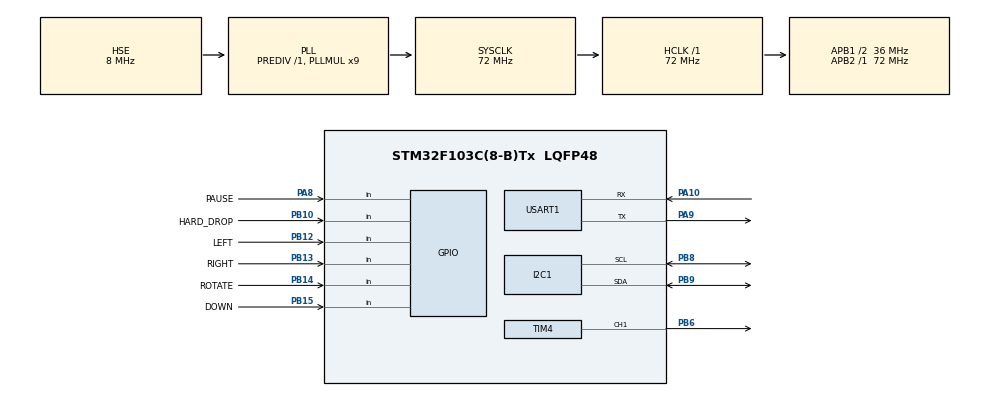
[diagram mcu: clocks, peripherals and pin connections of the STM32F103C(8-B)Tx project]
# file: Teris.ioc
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FREERTOS.Queues01=xInputQueue,16,uint16_t,0,Dynamic,NULL,NULL;xFrameQueue,1,uint16_t,0,Dynamic,NULL,NULL
FREERTOS.Tasks01=InputTask,27,192,StartInputTask,Default,NULL,Dynamic,NULL,NULL;GameTask,26,320,StartGameTask,Default,NULL,Dynamic,NULL,NULL;DisplayTask,25,384,StartDisplayTask,Default,NULL,Dynamic,NULL,NULL
FREERTOS.configCHECK_FOR_STACK_OVERFLOW=2
FREERTOS.configIDLE_SHOULD_YIELD=0
FREERTOS.configTOTAL_HEAP_SIZE=8192
FREERTOS.configUSE_MALLOC_FAILED_HOOK=1
Mcu.Family=STM32F1
Mcu.Name=STM32F103C(8-B)Tx
Mcu.Package=LQFP48
NVIC.PriorityGroup=NVIC_PRIORITYGROUP_4
NVIC.TIM2_IRQn=true\:15\:0\:false\:false\:true\:false\:false\:true\:true
NVIC.TimeBase=TIM2_IRQn
NVIC.TimeBaseIP=TIM2
NVIC.USART1_IRQn=true\:6\:0\:false\:false\:true\:true\:true\:true
PA10.Mode=Asynchronous
PA10.Signal=USART1_RX
PA13.Mode=Serial_Wire
PA13.Signal=SYS_JTMS-SWDIO
PA14.Mode=Serial_Wire
PA14.Signal=SYS_JTCK-SWCLK
PA8.GPIO_Label=PAUSE
PA8.GPIO_PuPd=GPIO_PULLUP
PA8.Signal=GPIO_Input
PA9.Mode=Asynchronous
PA9.Signal=USART1_TX
PB10.GPIO_Label=HARD_DROP
PB10.GPIO_PuPd=GPIO_PULLUP
PB10.Signal=GPIO_Input
PB12.GPIO_Label=LEFT
PB12.GPIO_PuPd=GPIO_PULLUP
PB12.Signal=GPIO_Input
PB13.GPIO_Label=RIGHT
PB13.GPIO_PuPd=GPIO_PULLUP
PB13.Signal=GPIO_Input
PB14.GPIO_Label=ROTATE
PB14.GPIO_PuPd=GPIO_PULLUP
PB14.Signal=GPIO_Input
PB15.GPIO_Label=DOWN
PB15.GPIO_PuPd=GPIO_PULLUP
PB15.Signal=GPIO_Input
PB6.Signal=S_TIM4_CH1
PB8.Mode=I2C
PB8.Signal=I2C1_SCL
PB9.Mode=I2C
PB9.Signal=I2C1_SDA
PD0-OSC_IN.Mode=HSE-External-Oscillator
PD0-OSC_IN.Signal=RCC_OSC_IN
PD1-OSC_OUT.Mode=HSE-External-Oscillator
PD1-OSC_OUT.Signal=RCC_OSC_OUT
ProjectManager.HeapSize=0x200
ProjectManager.StackSize=0x400
ProjectManager.TargetToolchain=MDK-ARM V5.32
RCC.AHBFreq_Value=72000000
RCC.APB1CLKDivider=RCC_HCLK_DIV2
RCC.APB1Freq_Value=36000000
RCC.APB1TimFreq_Value=72000000
RCC.APB2Freq_Value=72000000
RCC.APB2TimFreq_Value=72000000
RCC.HCLKFreq_Value=72000000
RCC.PLLMUL=RCC_PLL_MUL9
RCC.PLLSourceVirtual=RCC_PLLSOURCE_HSE
RCC.SYSCLKFreq_VALUE=72000000
RCC.SYSCLKSource=RCC_SYSCLKSOURCE_PLLCLK
RCC.USBFreq_Value=72000000
SH.S_TIM4_CH1.0=TIM4_CH1,PWM Generation1 CH1
TIM4.Channel-PWM\ Generation1\ CH1=TIM_CHANNEL_1
TIM4.OCPolarity-PWM\ Generation1\ CH1=TIM_OCPOLARITY_LOW
TIM4.Period=999
TIM4.Prescaler=71
USART1.VirtualMode=VM_ASYNC
VP_FREERTOS_VS_CMSIS_V2.Mode=CMSIS_V2
VP_SYS_VS_tim2.Mode=TIM2
board=custom

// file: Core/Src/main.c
/* USER CODE BEGIN Header */
/**
  ******************************************************************************
  * @file           : main.c
  * @brief          : Main program body
  ******************************************************************************
  * @attention
  *
  * Copyright (c) 2026 STMicroelectronics.
  * All rights reserved.
  *
  * This software is licensed under terms that can be found in the LICENSE file
  * in the root directory of this software component.
  * If no LICENSE file comes with this software, it is provided AS-IS.
  *
  ******************************************************************************
  */
/* USER CODE END Header */
#include "main.h"
#include "cmsis_os.h"

/* USER CODE BEGIN Includes */
#include "app_shared.h"
#include "app_diagnostics.h"

/* USER CODE END Includes */

I2C_HandleTypeDef hi2c1;

TIM_HandleTypeDef htim4;

UART_HandleTypeDef huart1;

/* Definitions for InputTask */
osThreadId_t InputTaskHandle;
const osThreadAttr_t InputTask_attributes = {
  .name = "InputTask",
  .stack_size = 192 * 4,
  .priority = (osPriority_t) osPriorityNormal3,
};
/* Definitions for GameTask */
osThreadId_t GameTaskHandle;
const osThreadAttr_t GameTask_attributes = {
  .name = "GameTask",
  .stack_size = 320 * 4,
  .priority = (osPriority_t) osPriorityNormal2,
};
/* Definitions for DisplayTask */
osThreadId_t DisplayTaskHandle;
const osThreadAttr_t DisplayTask_attributes = {
  .name = "DisplayTask",
  .stack_size = 384 * 4,
  .priority = (osPriority_t) osPriorityNormal1,
};
/* Definitions for xInputQueue */
osMessageQueueId_t xInputQueueHandle;
const osMessageQueueAttr_t xInputQueue_attributes = {
  .name = "xInputQueue"
};
/* Definitions for xFrameQueue */
osMessageQueueId_t xFrameQueueHandle;
const osMessageQueueAttr_t xFrameQueue_attributes = {
  .name = "xFrameQueue"
};

void SystemClock_Config(void);
static void MX_GPIO_Init(void);
static void MX_I2C1_Init(void);
static void MX_TIM4_Init(void);
static void MX_USART1_UART_Init(void);
void StartInputTask(void *argument);
void StartGameTask(void *argument);
void StartDisplayTask(void *argument);

int main(void)
{

  /* MCU Configuration--------------------------------------------------------*/

  /* Reset of all peripherals, Initializes the Flash interface and the Systick. */
  HAL_Init();

  /* Configure the system clock */
  SystemClock_Config();

  /* Initialize all configured peripherals */
  MX_GPIO_Init();
  MX_I2C1_Init();
  MX_TIM4_Init();
  MX_USART1_UART_Init();

  /* Init scheduler */
  if (osKernelInitialize()!=osOK) Error_Handler();

  /* Create the queue(s) */
  /* creation of xInputQueue */
  xInputQueueHandle = osMessageQueueNew (16, sizeof(uint16_t), &xInputQueue_attributes);

  /* creation of xFrameQueue */
  xFrameQueueHandle = osMessageQueueNew (1, sizeof(uint16_t), &xFrameQueue_attributes);

  /* Create the thread(s) */
  /* creation of InputTask */
  InputTaskHandle = osThreadNew(StartInputTask, NULL, &InputTask_attributes);

  /* creation of GameTask */
  GameTaskHandle = osThreadNew(StartGameTask, NULL, &GameTask_attributes);

  /* creation of DisplayTask */
  DisplayTaskHandle = osThreadNew(StartDisplayTask, NULL, &DisplayTask_attributes);

  /* USER CODE BEGIN RTOS_THREADS */
  if (!xInputQueueHandle || !xFrameQueueHandle || !InputTaskHandle ||
      !GameTaskHandle || !DisplayTaskHandle) app_fault(APP_FAULT_RTOS);
  /* add threads, ... */
  /* USER CODE END RTOS_THREADS */

  /* Start scheduler */
  if (osKernelStart()!=osOK) app_fault(APP_FAULT_RTOS);

  /* We should never get here as control is now taken by the scheduler */

  /* Infinite loop */
  while (1)
  {

  }
}

void SystemClock_Config(void)
{
  RCC_OscInitTypeDef RCC_OscInitStruct = {0};
  RCC_ClkInitTypeDef RCC_ClkInitStruct = {0};

  /** Initializes the RCC Oscillators according to the specified parameters
  * in the RCC_OscInitTypeDef structure.
  */
  RCC_OscInitStruct.OscillatorType = RCC_OSCILLATORTYPE_HSE;
  RCC_OscInitStruct.HSEState = RCC_HSE_ON;
  RCC_OscInitStruct.HSEPredivValue = RCC_HSE_PREDIV_DIV1;
  RCC_OscInitStruct.HSIState = RCC_HSI_ON;
  RCC_OscInitStruct.PLL.PLLState = RCC_PLL_ON;
  RCC_OscInitStruct.PLL.PLLSource = RCC_PLLSOURCE_HSE;
  RCC_OscInitStruct.PLL.PLLMUL = RCC_PLL_MUL9;
  if (HAL_RCC_OscConfig(&RCC_OscInitStruct) != HAL_OK)
  {
    Error_Handler();
  }

  /** Initializes the CPU, AHB and APB buses clocks
  */
  RCC_ClkInitStruct.ClockType = RCC_CLOCKTYPE_HCLK|RCC_CLOCKTYPE_SYSCLK
                              |RCC_CLOCKTYPE_PCLK1|RCC_CLOCKTYPE_PCLK2;
  RCC_ClkInitStruct.SYSCLKSource = RCC_SYSCLKSOURCE_PLLCLK;
  RCC_ClkInitStruct.AHBCLKDivider = RCC_SYSCLK_DIV1;
  RCC_ClkInitStruct.APB1CLKDivider = RCC_HCLK_DIV2;
  RCC_ClkInitStruct.APB2CLKDivider = RCC_HCLK_DIV1;

  if (HAL_RCC_ClockConfig(&RCC_ClkInitStruct, FLASH_LATENCY_2) != HAL_OK)
  {
    Error_Handler();
  }
}

static void MX_I2C1_Init(void)
{

  hi2c1.Instance = I2C1;
  hi2c1.Init.ClockSpeed = 100000;
  hi2c1.Init.DutyCycle = I2C_DUTYCYCLE_2;
  hi2c1.Init.OwnAddress1 = 0;
  hi2c1.Init.AddressingMode = I2C_ADDRESSINGMODE_7BIT;
  hi2c1.Init.DualAddressMode = I2C_DUALADDRESS_DISABLE;
  hi2c1.Init.OwnAddress2 = 0;
  hi2c1.Init.GeneralCallMode = I2C_GENERALCALL_DISABLE;
  hi2c1.Init.NoStretchMode = I2C_NOSTRETCH_DISABLE;
  if (HAL_I2C_Init(&hi2c1) != HAL_OK)
  {
    Error_Handler();
  }

}

static void MX_TIM4_Init(void)
{

  TIM_MasterConfigTypeDef sMasterConfig = {0};
  TIM_OC_InitTypeDef sConfigOC = {0};

  htim4.Instance = TIM4;
  htim4.Init.Prescaler = 71;
  htim4.Init.CounterMode = TIM_COUNTERMODE_UP;
  htim4.Init.Period = 999;
  htim4.Init.ClockDivision = TIM_CLOCKDIVISION_DIV1;
  htim4.Init.AutoReloadPreload = TIM_AUTORELOAD_PRELOAD_DISABLE;
  if (HAL_TIM_PWM_Init(&htim4) != HAL_OK)
  {
    Error_Handler();
  }
  sMasterConfig.MasterOutputTrigger = TIM_TRGO_RESET;
  sMasterConfig.MasterSlaveMode = TIM_MASTERSLAVEMODE_DISABLE;
  if (HAL_TIMEx_MasterConfigSynchronization(&htim4, &sMasterConfig) != HAL_OK)
  {
    Error_Handler();
  }
  sConfigOC.OCMode = TIM_OCMODE_PWM1;
  sConfigOC.Pulse = 0;
  sConfigOC.OCPolarity = TIM_OCPOLARITY_HIGH;
  sConfigOC.OCFastMode = TIM_OCFAST_DISABLE;
  if (HAL_TIM_PWM_ConfigChannel(&htim4, &sConfigOC, TIM_CHANNEL_1) != HAL_OK)
  {
    Error_Handler();
  }
  HAL_TIM_MspPostInit(&htim4);

}

static void MX_USART1_UART_Init(void)
{

  huart1.Instance = USART1;
  huart1.Init.BaudRate = 115200;
  huart1.Init.WordLength = UART_WORDLENGTH_8B;
  huart1.Init.StopBits = UART_STOPBITS_1;
  huart1.Init.Parity = UART_PARITY_NONE;
  huart1.Init.Mode = UART_MODE_TX_RX;
  huart1.Init.HwFlowCtl = UART_HWCONTROL_NONE;
  huart1.Init.OverSampling = UART_OVERSAMPLING_16;
  if (HAL_UART_Init(&huart1) != HAL_OK)
  {
    Error_Handler();
  }

}

static void MX_GPIO_Init(void)
{
  GPIO_InitTypeDef GPIO_InitStruct = {0};

  /* GPIO Ports Clock Enable */
  __HAL_RCC_GPIOD_CLK_ENABLE();
  __HAL_RCC_GPIOB_CLK_ENABLE();
  __HAL_RCC_GPIOA_CLK_ENABLE();

  /*Configure GPIO pins : HARD_DROP_Pin LEFT_Pin RIGHT_Pin ROTATE_Pin
                           DOWN_Pin */
  GPIO_InitStruct.Pin = HARD_DROP_Pin|LEFT_Pin|RIGHT_Pin|ROTATE_Pin
                          |DOWN_Pin;
  GPIO_InitStruct.Mode = GPIO_MODE_INPUT;
  GPIO_InitStruct.Pull = GPIO_PULLUP;
  HAL_GPIO_Init(GPIOB, &GPIO_InitStruct);

  /*Configure GPIO pin : PAUSE_Pin */
  GPIO_InitStruct.Pin = PAUSE_Pin;
  GPIO_InitStruct.Mode = GPIO_MODE_INPUT;
  GPIO_InitStruct.Pull = GPIO_PULLUP;
  HAL_GPIO_Init(PAUSE_GPIO_Port, &GPIO_InitStruct);

}

void StartInputTask(void *argument)
{
  /* USER CODE BEGIN 5 */
  /* Call the module in this existing CubeMX Task; never create a duplicate. */
  task_input_run(argument);
  /* USER CODE END 5 */
}

void StartGameTask(void *argument)
{
  /* USER CODE BEGIN StartGameTask */
  /* Call the module in this existing CubeMX Task; never create a duplicate. */
  task_game_run(argument);
  /* USER CODE END StartGameTask */
}

void StartDisplayTask(void *argument)
{
  /* USER CODE BEGIN StartDisplayTask */
  /* Call the module in this existing CubeMX Task; never create a duplicate. */
  task_display_run(argument);
  /* USER CODE END StartDisplayTask */
}

void HAL_TIM_PeriodElapsedCallback(TIM_HandleTypeDef *htim)
{
  if (htim->Instance == TIM2)
  {
    HAL_IncTick();
  }
}

void Error_Handler(void)
{
  __disable_irq();
  while (1)
  {
  }
}

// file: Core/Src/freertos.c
/* USER CODE BEGIN Header */
/**
  ******************************************************************************
  * File Name          : freertos.c
  * Description        : Code for freertos applications
  ******************************************************************************
  * @attention
  *
  * Copyright (c) 2026 STMicroelectronics.
  * All rights reserved.
  *
  * This software is licensed under terms that can be found in the LICENSE file
  * in the root directory of this software component.
  * If no LICENSE file comes with this software, it is provided AS-IS.
  *
  ******************************************************************************
  */
/* USER CODE END Header */

#include "FreeRTOS.h"
#include "task.h"
#include "main.h"

/* USER CODE BEGIN Includes */
#include "app_diagnostics.h"

/* USER CODE END Includes */

/* Hook prototypes */
void vApplicationStackOverflowHook(xTaskHandle xTask, signed char *pcTaskName);
void vApplicationMallocFailedHook(void);

/* USER CODE BEGIN 4 */
void vApplicationStackOverflowHook(xTaskHandle xTask, signed char *pcTaskName)
{
   (void)xTask; (void)pcTaskName;
   app_fault(APP_FAULT_STACK);
}
/* USER CODE END 4 */

/* USER CODE BEGIN 5 */
void vApplicationMallocFailedHook(void)
{
   app_fault(APP_FAULT_MALLOC);
}
/* USER CODE END 5 */
